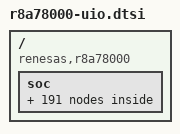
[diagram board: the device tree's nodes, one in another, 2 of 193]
// SPDX-License-Identifier: (GPL-2.0-only OR BSD-2-Clause)
/*
 * Device Tree Source fragment for UIO support on the R-Car X5H (R8A78000) SoC
 *
 * Copyright (C) 2025 Renesas Electronics Corp.
 */

#include <dt-bindings/ipmmu/rcar-ipmmu.h>
#include "r8a78000.dtsi"

/ {
	compatible = "renesas,r8a78000", "renesas,r8a78000-uio";

	soc: soc {
		imrlx7_ims00: ims@c1800000{
			compatible = "generic-uio";
			reg = <0 0xc1800000 0 0x10000>;
			interrupts = <GIC_SPI 606 IRQ_TYPE_LEVEL_HIGH>;
			clocks = <&scmi_clk X5H_CLOCK_ID_IMN_IMS00>;
			power-domains = <&scmi_devpd X5H_POWER_DOMAIN_ID_IM0>;
			linux,uio-name = "ims_00";
		};

		imrlx7_ims01: ims@c1810000{
			compatible = "generic-uio";
			reg = <0 0xc1810000 0 0x10000>;
			interrupts = <GIC_SPI 607 IRQ_TYPE_LEVEL_HIGH>;
			clocks = <&scmi_clk X5H_CLOCK_ID_IMN_IMS01>;
			power-domains = <&scmi_devpd X5H_POWER_DOMAIN_ID_IM0>;
			linux,uio-name = "ims_01";
		};

		imrlx7_ims02: ims@c1820000{
			compatible = "generic-uio";
			reg = <0 0xc1820000 0 0x10000>;
			interrupts = <GIC_SPI 608 IRQ_TYPE_LEVEL_HIGH>;
			clocks = <&scmi_clk X5H_CLOCK_ID_IMN_IMS02>;
			power-domains = <&scmi_devpd X5H_POWER_DOMAIN_ID_IM1>;
			linux,uio-name = "ims_02";
		};

		imrlx7_ims03: ims@c1830000{
			compatible = "generic-uio";
			reg = <0 0xc1830000 0 0x10000>;
			interrupts = <GIC_SPI 609 IRQ_TYPE_LEVEL_HIGH>;
			clocks = <&scmi_clk X5H_CLOCK_ID_IMN_IMS03>;
			power-domains = <&scmi_devpd X5H_POWER_DOMAIN_ID_IM1>;
			linux,uio-name = "ims_03";
		};

		imrlx7_imr00: imr@c1900000 {
			compatible = "generic-uio";
			reg = <0 0xc1900000 0 0x10000>;
			interrupts = <GIC_SPI 614 IRQ_TYPE_LEVEL_HIGH>;
			clocks = <&scmi_clk X5H_CLOCK_ID_IMN_IMR000>;
			power-domains = <&scmi_devpd X5H_POWER_DOMAIN_ID_IM0>;
			linux,uio-name = "imr_00";
		};

		imrlx7_imr01: imr@c1910000 {
			compatible = "generic-uio";
			reg = <0 0xc1910000 0 0x10000>;
			interrupts = <GIC_SPI 615 IRQ_TYPE_LEVEL_HIGH>;
			clocks = <&scmi_clk X5H_CLOCK_ID_IMN_IMR001>;
			power-domains = <&scmi_devpd X5H_POWER_DOMAIN_ID_IM1>;
			linux,uio-name = "imr_01";
		};

		imrlx7_ims10: ims@c1c00000 {
			compatible = "generic-uio";
			reg = <0 0xc1c00000 0 0x10000>;
			interrupts = <GIC_SPI 610 IRQ_TYPE_LEVEL_HIGH>;
			clocks = <&scmi_clk X5H_CLOCK_ID_IMS_IMS00>;
			power-domains = <&scmi_devpd X5H_POWER_DOMAIN_ID_IM1>;
			linux,uio-name = "ims_10";
		};

		imrlx7_ims11: ims@c1c10000 {
			compatible = "generic-uio";
			reg = <0 0xc1c10000 0 0x10000>;
			interrupts = <GIC_SPI 611 IRQ_TYPE_LEVEL_HIGH>;
			clocks = <&scmi_clk X5H_CLOCK_ID_IMS_IMS01>;
			power-domains = <&scmi_devpd X5H_POWER_DOMAIN_ID_IM2>;
			linux,uio-name = "ims_11";
		};

		imrlx7_ims12: ims@c1c20000 {
			compatible = "generic-uio";
			reg = <0 0xc1c20000 0 0x10000>;
			interrupts = <GIC_SPI 612 IRQ_TYPE_LEVEL_HIGH>;
			clocks = <&scmi_clk X5H_CLOCK_ID_IMS_IMS02>;
			power-domains = <&scmi_devpd X5H_POWER_DOMAIN_ID_IM3>;
			linux,uio-name = "ims_12";
		};

		imrlx7_ims13: ims@c1c30000 {
			compatible = "generic-uio";
			reg = <0 0xc1c30000 0 0x10000>;
			interrupts = <GIC_SPI 613 IRQ_TYPE_LEVEL_HIGH>;
			clocks = <&scmi_clk X5H_CLOCK_ID_IMS_IMS03>;
			power-domains = <&scmi_devpd X5H_POWER_DOMAIN_ID_IM3>;
			linux,uio-name = "ims_13";
		};

		imrlx7_imr10: imr@c1d00000 {
			compatible = "generic-uio";
			reg = <0 0xc1d00000 0 0x10000>;
			interrupts = <GIC_SPI 616 IRQ_TYPE_LEVEL_HIGH>;
			clocks = <&scmi_clk X5H_CLOCK_ID_IMS_IMR000>;
			power-domains = <&scmi_devpd X5H_POWER_DOMAIN_ID_IM2>;
			linux,uio-name = "imr_10";
		};

		imrlx7_imr11: imr@c1d10000 {
			compatible = "generic-uio";
			reg = <0 0xc1d10000 0 0x10000>;
			interrupts = <GIC_SPI 617 IRQ_TYPE_LEVEL_HIGH>;
			clocks = <&scmi_clk X5H_CLOCK_ID_IMS_IMR001>;
			power-domains = <&scmi_devpd X5H_POWER_DOMAIN_ID_IM3>;
			linux,uio-name = "imr_11";
		};

		cisp0: cisp@c4000000 {
			compatible = "generic-uio";
			reg = <0 0xc4000000 0 0x100000>;
			interrupts = <GIC_SPI 502 IRQ_TYPE_LEVEL_HIGH>;
			clocks = <&scmi_clk X5H_CLOCK_ID_ISP0>;
			power-domains = <&scmi_devpd X5H_POWER_DOMAIN_ID_VIO0>;
			linux,uio-name = "cisp_00";
		};

		cisp1: cisp@c4100000 {
			compatible = "generic-uio";
			reg = <0 0xc4100000 0 0x100000>;
			interrupts = <GIC_SPI 503 IRQ_TYPE_LEVEL_HIGH>;
			clocks = <&scmi_clk X5H_CLOCK_ID_ISP1>;
			power-domains = <&scmi_devpd X5H_POWER_DOMAIN_ID_VIO1>;
			linux,uio-name = "cisp_01";
		};

		cisp2: cisp@c4200000 {
			compatible = "generic-uio";
			reg = <0 0xc4200000 0 0x100000>;
			interrupts = <GIC_SPI 504 IRQ_TYPE_LEVEL_HIGH>;
			clocks = <&scmi_clk X5H_CLOCK_ID_ISP2>;
			power-domains = <&scmi_devpd X5H_POWER_DOMAIN_ID_VIO2>;
			linux,uio-name = "cisp_02";
		};

		cisp3: cisp@c4300000 {
			compatible = "generic-uio";
			reg = <0 0xc4300000 0 0x100000>;
			interrupts = <GIC_SPI 505 IRQ_TYPE_LEVEL_HIGH>;
			clocks = <&scmi_clk X5H_CLOCK_ID_ISP3>;
			power-domains = <&scmi_devpd X5H_POWER_DOMAIN_ID_VIO3>;
			linux,uio-name = "cisp_03";
		};

		tisp0: tisp@c4700000 {
			compatible = "generic-uio";
			reg = <0 0xc4700000 0 0x20000>;
			interrupts = <GIC_SPI 506 IRQ_TYPE_LEVEL_HIGH>;
			clocks = <&scmi_clk X5H_CLOCK_ID_ISPCS0>;
			power-domains = <&scmi_devpd X5H_POWER_DOMAIN_ID_VIO0>;
			linux,uio-name = "tisp_00";
		};

		tisp1: tisp@c4720000 {
			compatible = "generic-uio";
			reg = <0 0xc4720000 0 0x20000>;
			interrupts = <GIC_SPI 507 IRQ_TYPE_LEVEL_HIGH>;
			clocks = <&scmi_clk X5H_CLOCK_ID_ISPCS1>;
			power-domains = <&scmi_devpd X5H_POWER_DOMAIN_ID_VIO1>;
			linux,uio-name = "tisp_01";
		};

		tisp2: tisp@c4740000 {
			compatible = "generic-uio";
			reg = <0 0xc4740000 0 0x20000>;
			interrupts = <GIC_SPI 508 IRQ_TYPE_LEVEL_HIGH>;
			clocks = <&scmi_clk X5H_CLOCK_ID_ISPCS2>;
			power-domains = <&scmi_devpd X5H_POWER_DOMAIN_ID_VIO2>;
			linux,uio-name = "tisp_02";
		};

		tisp3: tisp@c4760000 {
			compatible = "generic-uio";
			reg = <0 0xc4760000 0 0x20000>;
			interrupts = <GIC_SPI 509 IRQ_TYPE_LEVEL_HIGH>;
			clocks = <&scmi_clk X5H_CLOCK_ID_ISPCS3>;
			power-domains = <&scmi_devpd X5H_POWER_DOMAIN_ID_VIO3>;
			linux,uio-name = "tisp_03";
		};
		vspx0: vspx@c4880000 {
			compatible = "generic-uio";
			reg = <0 0xc4880000 0 0x4000>;
			interrupts = <GIC_SPI 647 IRQ_TYPE_LEVEL_HIGH>;
			clocks = <&scmi_clk X5H_CLOCK_ID_VSPX0>;
			power-domains = <&scmi_devpd X5H_POWER_DOMAIN_ID_VIO0>;
			linux,uio-name = "vspx_00";
		};

		vspx1: vspx@c4884000 {
			compatible = "generic-uio";
			reg = <0 0xc4884000 0 0x4000>;
			interrupts = <GIC_SPI 648 IRQ_TYPE_LEVEL_HIGH>;
			clocks = <&scmi_clk X5H_CLOCK_ID_VSPX1>;
			power-domains = <&scmi_devpd X5H_POWER_DOMAIN_ID_VIO1>;
			linux,uio-name = "vspx_01";
		};

		vspx2: vspx@c4888000 {
			compatible = "generic-uio";
			reg = <0 0xc4888000 0 0x4000>;
			interrupts = <GIC_SPI 649 IRQ_TYPE_LEVEL_HIGH>;
			clocks = <&scmi_clk X5H_CLOCK_ID_VSPX2>;
			power-domains = <&scmi_devpd X5H_POWER_DOMAIN_ID_VIO2>;
			linux,uio-name = "vspx_02";
		};

		vspx3: vspx@c488c000 {
			compatible = "generic-uio";
			reg = <0 0xc488c000 0 0x4000>;
			interrupts = <GIC_SPI 650 IRQ_TYPE_LEVEL_HIGH>;
			clocks = <&scmi_clk X5H_CLOCK_ID_VSPX3>;
			power-domains = <&scmi_devpd X5H_POWER_DOMAIN_ID_VIO3>;
			linux,uio-name = "vspx_03";
		};

		fcpvx0: fcpvx@c48a4000 {
			compatible = "generic-uio";
			reg = <0 0xc48a4000 0 0x1000>;
			clocks = <&scmi_clk X5H_CLOCK_ID_FCPVX0>;
			power-domains = <&scmi_devpd X5H_POWER_DOMAIN_ID_VIO0>;
			linux,uio-name = "fcpvx_00";
		};

		fcpvx1: fcpvx@c48a5000 {
			compatible = "generic-uio";
			reg = <0 0xc48a5000 0 0x1000>;
			clocks = <&scmi_clk X5H_CLOCK_ID_FCPVX1>;
			power-domains = <&scmi_devpd X5H_POWER_DOMAIN_ID_VIO1>;
			linux,uio-name = "fcpvx_01";
		};

		fcpvx2: fcpvx@c48a6000 {
			compatible = "generic-uio";
			reg = <0 0xc48a6000 0 0x1000>;
			clocks = <&scmi_clk X5H_CLOCK_ID_FCPVX2>;
			power-domains = <&scmi_devpd X5H_POWER_DOMAIN_ID_VIO2>;
			linux,uio-name = "fcpvx_02";
		};

		fcpvx3: fcpvx@c48a7000 {
			compatible = "generic-uio";
			reg = <0 0xc48a7000 0 0x1000>;
			clocks = <&scmi_clk X5H_CLOCK_ID_FCPVX3>;
			power-domains = <&scmi_devpd X5H_POWER_DOMAIN_ID_VIO3>;
			linux,uio-name = "fcpvx_03";
		};

		vcp5_0: dspss@c3000000 {
			compatible = "generic-uio";
			reg = <0 0xc3000000 0 0x10000>;
			interrupts = <GIC_SPI 651 IRQ_TYPE_LEVEL_HIGH>;
			clocks = <&scmi_clk X5H_CLOCK_ID_VIPN_VCP5X0>;
			power-domains = <&scmi_devpd X5H_POWER_DOMAIN_ID_VCN>;
			linux,uio-name = "vcp5_00";
		};

		vcp5_00_01 {
			compatible = "generic-uio";
			reg = <0 0xc3000000 0 0x10000>;
			interrupts = <GIC_SPI 655 IRQ_TYPE_LEVEL_HIGH>;
			clocks = <&scmi_clk X5H_CLOCK_ID_VIPN_VCP5X0>;
			power-domains = <&scmi_devpd X5H_POWER_DOMAIN_ID_VCN>;
			linux,uio-name = "irq_vcp5_00_01";
		};

		vcp5_1: dspss@c3002000 {
			compatible = "generic-uio";
			reg = <0 0xc3002000 0 0x10000>;
			interrupts = <GIC_SPI 652 IRQ_TYPE_LEVEL_HIGH>;
			clocks = <&scmi_clk X5H_CLOCK_ID_VIPN_VCP5X0>;
			power-domains = <&scmi_devpd X5H_POWER_DOMAIN_ID_VCN>;
			linux,uio-name = "vcp5_01";
		};

		vcp5_01_01 {
			compatible = "generic-uio";
			reg = <0 0xc3002000 0 0x10000>;
			interrupts = <GIC_SPI 656 IRQ_TYPE_LEVEL_HIGH>;
			clocks = <&scmi_clk X5H_CLOCK_ID_VIPN_VCP5X0>;
			power-domains = <&scmi_devpd X5H_POWER_DOMAIN_ID_VCN>;
			linux,uio-name = "irq_vcp5_01_01";
		};

		vcp5_2: dspss@c3400000 {
			compatible = "generic-uio";
			reg = <0 0xc3400000 0 0x10000>;
			interrupts = <GIC_SPI 653 IRQ_TYPE_LEVEL_HIGH>;
			clocks = <&scmi_clk X5H_CLOCK_ID_VIPN_VCP5X1>;
			power-domains = <&scmi_devpd X5H_POWER_DOMAIN_ID_VCS>;
			linux,uio-name = "vcp5_02";
		};

		vcp5_02_01 {
			compatible = "generic-uio";
			reg = <0 0xc3400000 0 0x10000>;
			interrupts = <GIC_SPI 657 IRQ_TYPE_LEVEL_HIGH>;
			clocks = <&scmi_clk X5H_CLOCK_ID_VIPN_VCP5X1>;
			power-domains = <&scmi_devpd X5H_POWER_DOMAIN_ID_VCS>;
			linux,uio-name = "irq_vcp5_02_01";
		};

		vcp5_3: dspss@c3402000 {
			compatible = "generic-uio";
			reg = <0 0xc3402000 0 0x10000>;
			interrupts = <GIC_SPI 654 IRQ_TYPE_LEVEL_HIGH>;
			clocks = <&scmi_clk X5H_CLOCK_ID_VIPN_VCP5X1>;
			power-domains = <&scmi_devpd X5H_POWER_DOMAIN_ID_VCS>;
			linux,uio-name = "vcp5_03";
		};

		vcp5_03_01 {
			compatible = "generic-uio";
			reg = <0 0xc3402000 0 0x10000>;
			interrupts = <GIC_SPI 658 IRQ_TYPE_LEVEL_HIGH>;
			clocks = <&scmi_clk X5H_CLOCK_ID_VIPN_VCP5X1>;
			power-domains = <&scmi_devpd X5H_POWER_DOMAIN_ID_VCS>;
			linux,uio-name = "irq_vcp5_03_01";
		};

		fcpc0: fcpc@c3008000 {
			compatible = "generic-uio";
			reg = <0 0xc3008000 0 0x1000>;
			clocks = <&scmi_clk X5H_CLOCK_ID_VIPN_FCPCS0>;
			power-domains = <&scmi_devpd X5H_POWER_DOMAIN_ID_VCN>;
			linux,uio-name = "fcpc_00";
		};

		fcpc1: fcpc@c3009000 {
			compatible = "generic-uio";
			reg = <0 0xc3009000 0 0x1000>;
			clocks = <&scmi_clk X5H_CLOCK_ID_VIPN_FCPCS0>;
			power-domains = <&scmi_devpd X5H_POWER_DOMAIN_ID_VCN>;
			linux,uio-name = "fcpc_01";
		};

		fcpc2: fcpc@c3408000 {
			compatible = "generic-uio";
			reg = <0 0xc3408000 0 0x1000>;
			clocks = <&scmi_clk X5H_CLOCK_ID_VIPN_FCPCS1>;
			power-domains = <&scmi_devpd X5H_POWER_DOMAIN_ID_VCS>;
			linux,uio-name = "fcpc_02";
		};

		fcpc3: fcpc@c3409000 {
			compatible = "generic-uio";
			reg = <0 0xc3409000 0 0x1000>;
			clocks = <&scmi_clk X5H_CLOCK_ID_VIPN_FCPCS1>;
			power-domains = <&scmi_devpd X5H_POWER_DOMAIN_ID_VCS>;
			linux,uio-name = "fcpc_03";
		};

		rsipe0: rsipe@19300000 {
			compatible = "generic-uio";
			reg = <0 0x19300000 0 0x8000>;
			interrupts = <GIC_SPI 4187 IRQ_TYPE_LEVEL_HIGH>;
			clocks = <&scmi_clk X5H_CLOCK_ID_CRAC0>;
			//power-domains = <&scmi_devpd X5H_POWER_DOMAIN_ID_PD_APL>;
			resets = <&scmi_reset X5H_RESET_DOMAIN_ID_CRAC0>;
			linux,uio-name = "rsip_e_00";
		};

		rsipe1: rsipe@19308000 {
			compatible = "generic-uio";
			reg = <0 0x19308000 0 0x8000>;
			interrupts = <GIC_SPI 4188 IRQ_TYPE_LEVEL_HIGH>;
			clocks = <&scmi_clk X5H_CLOCK_ID_CRAC1>;
			//power-domains = <&scmi_devpd X5H_POWER_DOMAIN_ID_PD_APL>;
			resets = <&scmi_reset X5H_RESET_DOMAIN_ID_CRAC1>;
			linux,uio-name = "rsip_e_01";
		};

		rsipe2: rsipe@19310000 {
			compatible = "generic-uio";
			reg = <0 0x19310000 0 0x8000>;
			interrupts = <GIC_SPI 4189 IRQ_TYPE_LEVEL_HIGH>;
			clocks = <&scmi_clk X5H_CLOCK_ID_CRAC2>;
			//power-domains = <&scmi_devpd X5H_POWER_DOMAIN_ID_PD_APL>;
			resets = <&scmi_reset X5H_RESET_DOMAIN_ID_CRAC2>;
			linux,uio-name = "rsip_e_02";
		};

		rsipe3: rsipe@19318000 {
			compatible = "generic-uio";
			reg = <0 0x19318000 0 0x8000>;
			interrupts = <GIC_SPI 4190 IRQ_TYPE_LEVEL_HIGH>;
			clocks = <&scmi_clk X5H_CLOCK_ID_CRAC3>;
			//power-domains = <&scmi_devpd X5H_POWER_DOMAIN_ID_PD_APL>;
			resets = <&scmi_reset X5H_RESET_DOMAIN_ID_CRAC3>;
			linux,uio-name = "rsip_e_03";
		};

		rsipe4: rsipe@19320000 {
			compatible = "generic-uio";
			reg = <0 0x19320000 0 0x8000>;
			interrupts = <GIC_SPI 4191 IRQ_TYPE_LEVEL_HIGH>;
			clocks = <&scmi_clk X5H_CLOCK_ID_CRAC4>;
			//power-domains = <&scmi_devpd X5H_POWER_DOMAIN_ID_PD_APL>;
			resets = <&scmi_reset X5H_RESET_DOMAIN_ID_CRAC4>;
			linux,uio-name = "rsip_e_04";
		};

		rsipe5: rsipe@19328000 {
			compatible = "generic-uio";
			reg = <0 0x19328000 0 0x8000>;
			interrupts = <GIC_SPI 4192 IRQ_TYPE_LEVEL_HIGH>;
			clocks = <&scmi_clk X5H_CLOCK_ID_CRAC5>;
			//power-domains = <&scmi_devpd X5H_POWER_DOMAIN_ID_PD_APL>;
			resets = <&scmi_reset X5H_RESET_DOMAIN_ID_CRAC5>;
			linux,uio-name = "rsip_e_05";
		};

		rsipe6: rsipe@19330000 {
			compatible = "generic-uio";
			reg = <0 0x19330000 0 0x8000>;
			interrupts = <GIC_SPI 4193 IRQ_TYPE_LEVEL_HIGH>;
			clocks = <&scmi_clk X5H_CLOCK_ID_CRAC6>;
			//power-domains = <&scmi_devpd X5H_POWER_DOMAIN_ID_PD_APL>;
			resets = <&scmi_reset X5H_RESET_DOMAIN_ID_CRAC6>;
			linux,uio-name = "rsip_e_06";
		};

		rsipe7: rsipe@19338000 {
			compatible = "generic-uio";
			reg = <0 0x19338000 0 0x8000>;
			interrupts = <GIC_SPI 4194 IRQ_TYPE_LEVEL_HIGH>;
			clocks = <&scmi_clk X5H_CLOCK_ID_CRAC7>;
			//power-domains = <&scmi_devpd X5H_POWER_DOMAIN_ID_PD_APL>;
			resets = <&scmi_reset X5H_RESET_DOMAIN_ID_CRAC7>;
			linux,uio-name = "rsip_e_07";
		};

		rsipe8: rsipe@19340000 {
			compatible = "generic-uio";
			reg = <0 0x19340000 0 0x8000>;
			interrupts = <GIC_SPI 4195 IRQ_TYPE_LEVEL_HIGH>;
			clocks = <&scmi_clk X5H_CLOCK_ID_CRAC8>;
			//power-domains = <&scmi_devpd X5H_POWER_DOMAIN_ID_PD_APL>;
			resets = <&scmi_reset X5H_RESET_DOMAIN_ID_CRAC8>;
			linux,uio-name = "rsip_e_08";
		};

		rsipe9: rsipe@19348000 {
			compatible = "generic-uio";
			reg = <0 0x19348000 0 0x8000>;
			interrupts = <GIC_SPI 4196 IRQ_TYPE_LEVEL_HIGH>;
			clocks = <&scmi_clk X5H_CLOCK_ID_CRAC9>;
			//power-domains = <&scmi_devpd X5H_POWER_DOMAIN_ID_PD_APL>;
			resets = <&scmi_reset X5H_RESET_DOMAIN_ID_CRAC9>;
			linux,uio-name = "rsip_e_09";
		};

		rsipe10: rsipe@19350000 {
			compatible = "generic-uio";
			reg = <0 0x19350000 0 0x8000>;
			interrupts = <GIC_SPI 4197 IRQ_TYPE_LEVEL_HIGH>;
			clocks = <&scmi_clk X5H_CLOCK_ID_CRAC10>;
			//power-domains = <&scmi_devpd X5H_POWER_DOMAIN_ID_PD_APL>;
			resets = <&scmi_reset X5H_RESET_DOMAIN_ID_CRAC10>;
			linux,uio-name = "rsip_e_10";
		};

		rsipe11: rsipe@19358000 {
			compatible = "generic-uio";
			reg = <0 0x19358000 0 0x8000>;
			interrupts = <GIC_SPI 4198 IRQ_TYPE_LEVEL_HIGH>;
			clocks = <&scmi_clk X5H_CLOCK_ID_CRAC11>;
			//power-domains = <&scmi_devpd X5H_POWER_DOMAIN_ID_PD_APL>;
			resets = <&scmi_reset X5H_RESET_DOMAIN_ID_CRAC11>;
			linux,uio-name = "rsip_e_11";
		};

		rsipe12: rsipe@19360000 {
			compatible = "generic-uio";
			reg = <0 0x19360000 0 0x8000>;
			interrupts = <GIC_SPI 4199 IRQ_TYPE_LEVEL_HIGH>;
			clocks = <&scmi_clk X5H_CLOCK_ID_CRAC12>;
			//power-domains = <&scmi_devpd X5H_POWER_DOMAIN_ID_PD_APL>;
			resets = <&scmi_reset X5H_RESET_DOMAIN_ID_CRAC12>;
			linux,uio-name = "rsip_e_12";
		};

		rsipe13: rsipe@19368000 {
			compatible = "generic-uio";
			reg = <0 0x19368000 0 0x8000>;
			interrupts = <GIC_SPI 4200 IRQ_TYPE_LEVEL_HIGH>;
			clocks = <&scmi_clk X5H_CLOCK_ID_CRAC13>;
			//power-domains = <&scmi_devpd X5H_POWER_DOMAIN_ID_PD_APL>;
			resets = <&scmi_reset X5H_RESET_DOMAIN_ID_CRAC13>;
			linux,uio-name = "rsip_e_13";
		};

		rsipe14: rsipe@19370000 {
			compatible = "generic-uio";
			reg = <0 0x19370000 0 0x8000>;
			interrupts = <GIC_SPI 4201 IRQ_TYPE_LEVEL_HIGH>;
			clocks = <&scmi_clk X5H_CLOCK_ID_CRAC14>;
			//power-domains = <&scmi_devpd X5H_POWER_DOMAIN_ID_PD_APL>;
			resets = <&scmi_reset X5H_RESET_DOMAIN_ID_CRAC14>;
			linux,uio-name = "rsip_e_14";
		};

		rsipe15: rsipe@19378000 {
			compatible = "generic-uio";
			reg = <0 0x19378000 0 0x8000>;
			interrupts = <GIC_SPI 4202 IRQ_TYPE_LEVEL_HIGH>;
			clocks = <&scmi_clk X5H_CLOCK_ID_CRAC15>;
			//power-domains = <&scmi_devpd X5H_POWER_DOMAIN_ID_PD_APL>;
			resets = <&scmi_reset X5H_RESET_DOMAIN_ID_CRAC15>;
			linux,uio-name = "rsip_e_15";
		};

		rsipe16: rsipe@19380000 {
			compatible = "generic-uio";
			reg = <0 0x19380000 0 0x8000>;
			interrupts = <GIC_SPI 4203 IRQ_TYPE_LEVEL_HIGH>;
			clocks = <&scmi_clk X5H_CLOCK_ID_CRAC16>;
			//power-domains = <&scmi_devpd X5H_POWER_DOMAIN_ID_PD_APL>;
			resets = <&scmi_reset X5H_RESET_DOMAIN_ID_CRAC16>;
			linux,uio-name = "rsip_e_16";
		};

		rsipe17: rsipe@19388000 {
			compatible = "generic-uio";
			reg = <0 0x19388000 0 0x8000>;
			interrupts = <GIC_SPI 4204 IRQ_TYPE_LEVEL_HIGH>;
			clocks = <&scmi_clk X5H_CLOCK_ID_CRAC17>;
			//power-domains = <&scmi_devpd X5H_POWER_DOMAIN_ID_PD_APL>;
			resets = <&scmi_reset X5H_RESET_DOMAIN_ID_CRAC17>;
			linux,uio-name = "rsip_e_17";
		};

		rsipe18: rsipe@19390000 {
			compatible = "generic-uio";
			reg = <0 0x19390000 0 0x8000>;
			interrupts = <GIC_SPI 4205 IRQ_TYPE_LEVEL_HIGH>;
			clocks = <&scmi_clk X5H_CLOCK_ID_CRAC18>;
			//power-domains = <&scmi_devpd X5H_POWER_DOMAIN_ID_PD_APL>;
			resets = <&scmi_reset X5H_RESET_DOMAIN_ID_CRAC18>;
			linux,uio-name = "rsip_e_18";
		};

		rsipe19: rsipe@19398000 {
			compatible = "generic-uio";
			reg = <0 0x19398000 0 0x8000>;
			interrupts = <GIC_SPI 4206 IRQ_TYPE_LEVEL_HIGH>;
			clocks = <&scmi_clk X5H_CLOCK_ID_CRAC19>;
			//power-domains = <&scmi_devpd X5H_POWER_DOMAIN_ID_PD_APL>;
			resets = <&scmi_reset X5H_RESET_DOMAIN_ID_CRAC19>;
			linux,uio-name = "rsip_e_19";
		};

		rsipm: rsipm@18980000 {
			compatible = "generic-uio";
			reg = <0 0x18980000 0 0x10000>;
			linux,uio-name = "rsip_m_ts_cmd_00";
		};

		rsipm_reserved_mem1: rsipm@10100000 {
			compatible = "generic-uio";
			reg = <0 0x10100000 0 0x100000>;
			linux,uio-name = "rsip_m_shared_01";
		};

		rsipm_reserved_mem2: rsipm@4d000000 {
			compatible = "generic-uio";
			reg = <0 0x4d000000 0 0x600000>;
			linux,uio-name = "rsip_m_shared_02";
		};

		rsipe00: rsipe@19440000 {
			compatible = "generic-uio";
			reg = <0 0x19440000 0 0x1000>;
			linux,uio-name = "rsip_e_stb_00";
		};

		ostm0: ostm@1c060000 {
			compatible = "generic-uio";
			reg = <0 0x1c060000 0 0x1000>;
			interrupts = <GIC_SPI 4135 IRQ_TYPE_LEVEL_HIGH>;
			clocks = <&scmi_clk X5H_CLOCK_ID_OSTM0>;
			//power-domains = <&scmi_devpd X5H_POWER_DOMAIN_ID_PD_APL>;
			resets = <&scmi_reset X5H_RESET_DOMAIN_ID_OSTM0>;
			linux,uio-name = "ostm_00";
		};

		ostm1: ostm@1c061000 {
			compatible = "generic-uio";
			reg = <0 0x1c061000 0 0x1000>;
			interrupts = <GIC_SPI 4136 IRQ_TYPE_LEVEL_HIGH>;
			clocks = <&scmi_clk X5H_CLOCK_ID_OSTM1>;
			//power-domains = <&scmi_devpd X5H_POWER_DOMAIN_ID_PD_APL>;
			resets = <&scmi_reset X5H_RESET_DOMAIN_ID_OSTM1>;
			linux,uio-name = "ostm_01";
		};

		ostm2: ostm@1c062000 {
			compatible = "generic-uio";
			reg = <0 0x1c062000 0 0x1000>;
			interrupts = <GIC_SPI 4137 IRQ_TYPE_LEVEL_HIGH>;
			clocks = <&scmi_clk X5H_CLOCK_ID_OSTM2>;
			//power-domains = <&scmi_devpd X5H_POWER_DOMAIN_ID_PD_APL>;
			resets = <&scmi_reset X5H_RESET_DOMAIN_ID_OSTM2>;
			linux,uio-name = "ostm_02";
		};

		ostm3: ostm@1c063000 {
			compatible = "generic-uio";
			reg = <0 0x1c063000 0 0x1000>;
			interrupts = <GIC_SPI 4138 IRQ_TYPE_LEVEL_HIGH>;
			clocks = <&scmi_clk X5H_CLOCK_ID_OSTM3>;
			//power-domains = <&scmi_devpd X5H_POWER_DOMAIN_ID_PD_APL>;
			resets = <&scmi_reset X5H_RESET_DOMAIN_ID_OSTM3>;
			linux,uio-name = "ostm_03";
		};

		ostm4: ostm@1c064000 {
			compatible = "generic-uio";
			reg = <0 0x1c064000 0 0x1000>;
			interrupts = <GIC_SPI 4139 IRQ_TYPE_LEVEL_HIGH>;
			clocks = <&scmi_clk X5H_CLOCK_ID_OSTM4>;
			//power-domains = <&scmi_devpd X5H_POWER_DOMAIN_ID_PD_APL>;
			resets = <&scmi_reset X5H_RESET_DOMAIN_ID_OSTM4>;
			linux,uio-name = "ostm_04";
		};

		ostm5: ostm@1c065000 {
			compatible = "generic-uio";
			reg = <0 0x1c065000 0 0x1000>;
			interrupts = <GIC_SPI 4140 IRQ_TYPE_LEVEL_HIGH>;
			clocks = <&scmi_clk X5H_CLOCK_ID_OSTM5>;
			//power-domains = <&scmi_devpd X5H_POWER_DOMAIN_ID_PD_APL>;
			resets = <&scmi_reset X5H_RESET_DOMAIN_ID_OSTM5>;
			linux,uio-name = "ostm_05";
		};

		vin_00: video@c4900000 {
			compatible = "generic-uio";
			reg = <0 0xc4900000 0 0x1000>;
			interrupts = <GIC_SPI 510 IRQ_TYPE_LEVEL_HIGH>;
			power-domains = <&scmi_devpd X5H_POWER_DOMAIN_ID_VIO0>;
			clocks = <&scmi_clk X5H_CLOCK_ID_VIN000>;
			resets = <&scmi_reset X5H_RESET_DOMAIN_ID_VIN000>;
			linux,uio-name = "vin_00";
		};

		vin_01: video@c4901000 {
			compatible = "generic-uio";
			reg = <0 0xc4901000 0 0x1000>;
			interrupts = <GIC_SPI 511 IRQ_TYPE_LEVEL_HIGH>;
			power-domains = <&scmi_devpd X5H_POWER_DOMAIN_ID_VIO0>;
			clocks = <&scmi_clk X5H_CLOCK_ID_VIN001>;
			resets = <&scmi_reset X5H_RESET_DOMAIN_ID_VIN001>;
			linux,uio-name = "vin_01";
		};

		vin_02: video@c4902000 {
			compatible = "generic-uio";
			reg = <0 0xc4902000 0 0x1000>;
			interrupts = <GIC_SPI 512 IRQ_TYPE_LEVEL_HIGH>;
			power-domains = <&scmi_devpd X5H_POWER_DOMAIN_ID_VIO0>;
			clocks = <&scmi_clk X5H_CLOCK_ID_VIN002>;
			resets = <&scmi_reset X5H_RESET_DOMAIN_ID_VIN002>;
			linux,uio-name = "vin_02";
		};

		vin_03: video@c4903000 {
			compatible = "generic-uio";
			reg = <0 0xc4903000 0 0x1000>;
			interrupts = <GIC_SPI 513 IRQ_TYPE_LEVEL_HIGH>;
			power-domains = <&scmi_devpd X5H_POWER_DOMAIN_ID_VIO0>;
			clocks = <&scmi_clk X5H_CLOCK_ID_VIN003>;
			resets = <&scmi_reset X5H_RESET_DOMAIN_ID_VIN003>;
			linux,uio-name = "vin_03";
		};

		vin_04: video@c4904000 {
			compatible = "generic-uio";
			reg = <0 0xc4904000 0 0x1000>;
			interrupts = <GIC_SPI 514 IRQ_TYPE_LEVEL_HIGH>;
			power-domains = <&scmi_devpd X5H_POWER_DOMAIN_ID_VIO0>;
			clocks = <&scmi_clk X5H_CLOCK_ID_VIN004>;
			resets = <&scmi_reset X5H_RESET_DOMAIN_ID_VIN004>;
			linux,uio-name = "vin_04";
		};

		vin_05: video@c4905000 {
			compatible = "generic-uio";
			reg = <0 0xc4905000 0 0x1000>;
			interrupts = <GIC_SPI 515 IRQ_TYPE_LEVEL_HIGH>;
			power-domains = <&scmi_devpd X5H_POWER_DOMAIN_ID_VIO0>;
			clocks = <&scmi_clk X5H_CLOCK_ID_VIN005>;
			resets = <&scmi_reset X5H_RESET_DOMAIN_ID_VIN005>;
			linux,uio-name = "vin_05";
		};

		vin_06: video@c4906000 {
			compatible = "generic-uio";
			reg = <0 0xc4906000 0 0x1000>;
			interrupts = <GIC_SPI 516 IRQ_TYPE_LEVEL_HIGH>;
			power-domains = <&scmi_devpd X5H_POWER_DOMAIN_ID_VIO0>;
			clocks = <&scmi_clk X5H_CLOCK_ID_VIN006>;
			resets = <&scmi_reset X5H_RESET_DOMAIN_ID_VIN006>;
			linux,uio-name = "vin_06";
		};

		vin_07: video@c4907000 {
			compatible = "generic-uio";
			reg = <0 0xc4907000 0 0x1000>;
			interrupts = <GIC_SPI 517 IRQ_TYPE_LEVEL_HIGH>;
			power-domains = <&scmi_devpd X5H_POWER_DOMAIN_ID_VIO0>;
			clocks = <&scmi_clk X5H_CLOCK_ID_VIN007>;
			resets = <&scmi_reset X5H_RESET_DOMAIN_ID_VIN007>;
			linux,uio-name = "vin_07";
		};

		vin_10: video@c4908000 {
			compatible = "generic-uio";
			reg = <0 0xc4908000 0 0x1000>;
			interrupts = <GIC_SPI 518 IRQ_TYPE_LEVEL_HIGH>;
			power-domains = <&scmi_devpd X5H_POWER_DOMAIN_ID_VIO0>;
			clocks = <&scmi_clk X5H_CLOCK_ID_VIN010>;
			resets = <&scmi_reset X5H_RESET_DOMAIN_ID_VIN010>;
			linux,uio-name = "vin_10";
		};

		vin_11: video@c4909000 {
			compatible = "generic-uio";
			reg = <0 0xc4909000 0 0x1000>;
			interrupts = <GIC_SPI 519 IRQ_TYPE_LEVEL_HIGH>;
			power-domains = <&scmi_devpd X5H_POWER_DOMAIN_ID_VIO0>;
			clocks = <&scmi_clk X5H_CLOCK_ID_VIN011>;
			resets = <&scmi_reset X5H_RESET_DOMAIN_ID_VIN011>;
			linux,uio-name = "vin_11";
		};

		vin_12: video@c490a000 {
			compatible = "generic-uio";
			reg = <0 0xc490a000 0 0x1000>;
			interrupts = <GIC_SPI 520 IRQ_TYPE_LEVEL_HIGH>;
			power-domains = <&scmi_devpd X5H_POWER_DOMAIN_ID_VIO0>;
			clocks = <&scmi_clk X5H_CLOCK_ID_VIN012>;
			resets = <&scmi_reset X5H_RESET_DOMAIN_ID_VIN012>;
			linux,uio-name = "vin_12";
		};

		vin_13: video@c490b000 {
			compatible = "generic-uio";
			reg = <0 0xc490b000 0 0x1000>;
			interrupts = <GIC_SPI 521 IRQ_TYPE_LEVEL_HIGH>;
			power-domains = <&scmi_devpd X5H_POWER_DOMAIN_ID_VIO0>;
			clocks = <&scmi_clk X5H_CLOCK_ID_VIN013>;
			resets = <&scmi_reset X5H_RESET_DOMAIN_ID_VIN013>;
			linux,uio-name = "vin_13";
		};

		vin_14: video@c490c000 {
			compatible = "generic-uio";
			reg = <0 0xc490c000 0 0x1000>;
			interrupts = <GIC_SPI 522 IRQ_TYPE_LEVEL_HIGH>;
			power-domains = <&scmi_devpd X5H_POWER_DOMAIN_ID_VIO0>;
			clocks = <&scmi_clk X5H_CLOCK_ID_VIN014>;
			resets = <&scmi_reset X5H_RESET_DOMAIN_ID_VIN014>;
			linux,uio-name = "vin_14";
		};

		vin_15: video@c490d000 {
			compatible = "generic-uio";
			reg = <0 0xc490d000 0 0x1000>;
			interrupts = <GIC_SPI 523 IRQ_TYPE_LEVEL_HIGH>;
			power-domains = <&scmi_devpd X5H_POWER_DOMAIN_ID_VIO0>;
			clocks = <&scmi_clk X5H_CLOCK_ID_VIN015>;
			resets = <&scmi_reset X5H_RESET_DOMAIN_ID_VIN015>;
			linux,uio-name = "vin_15";
		};

		vin_16: video@c490e000 {
			compatible = "generic-uio";
			reg = <0 0xc490e000 0 0x1000>;
			interrupts = <GIC_SPI 524 IRQ_TYPE_LEVEL_HIGH>;
			power-domains = <&scmi_devpd X5H_POWER_DOMAIN_ID_VIO0>;
			clocks = <&scmi_clk X5H_CLOCK_ID_VIN016>;
			resets = <&scmi_reset X5H_RESET_DOMAIN_ID_VIN016>;
			linux,uio-name = "vin_16";
		};

		vin_17: video@c490f000 {
			compatible = "generic-uio";
			reg = <0 0xc490f000 0 0x1000>;
			interrupts = <GIC_SPI 525 IRQ_TYPE_LEVEL_HIGH>;
			power-domains = <&scmi_devpd X5H_POWER_DOMAIN_ID_VIO0>;
			clocks = <&scmi_clk X5H_CLOCK_ID_VIN017>;
			resets = <&scmi_reset X5H_RESET_DOMAIN_ID_VIN017>;
			linux,uio-name = "vin_17";
		};

		vin_20: video@c4910000 {
			compatible = "generic-uio";
			reg = <0 0xc4910000 0 0x1000>;
			interrupts = <GIC_SPI 526 IRQ_TYPE_LEVEL_HIGH>;
			power-domains = <&scmi_devpd X5H_POWER_DOMAIN_ID_VIO0>;
			clocks = <&scmi_clk X5H_CLOCK_ID_VIN020>;
			resets = <&scmi_reset X5H_RESET_DOMAIN_ID_VIN020>;
			linux,uio-name = "vin_20";
		};

		vin_21: video@c4911000 {
			compatible = "generic-uio";
			reg = <0 0xc4911000 0 0x1000>;
			interrupts = <GIC_SPI 527 IRQ_TYPE_LEVEL_HIGH>;
			power-domains = <&scmi_devpd X5H_POWER_DOMAIN_ID_VIO0>;
			clocks = <&scmi_clk X5H_CLOCK_ID_VIN021>;
			resets = <&scmi_reset X5H_RESET_DOMAIN_ID_VIN021>;
			linux,uio-name = "vin_21";
		};

		vin_22: video@c4912000 {
			compatible = "generic-uio";
			reg = <0 0xc4912000 0 0x1000>;
			interrupts = <GIC_SPI 528 IRQ_TYPE_LEVEL_HIGH>;
			power-domains = <&scmi_devpd X5H_POWER_DOMAIN_ID_VIO0>;
			clocks = <&scmi_clk X5H_CLOCK_ID_VIN022>;
			resets = <&scmi_reset X5H_RESET_DOMAIN_ID_VIN022>;
			linux,uio-name = "vin_22";
		};

		vin_23: video@c4913000 {
			compatible = "generic-uio";
			reg = <0 0xc4913000 0 0x1000>;
			interrupts = <GIC_SPI 529 IRQ_TYPE_LEVEL_HIGH>;
			power-domains = <&scmi_devpd X5H_POWER_DOMAIN_ID_VIO0>;
			clocks = <&scmi_clk X5H_CLOCK_ID_VIN023>;
			resets = <&scmi_reset X5H_RESET_DOMAIN_ID_VIN023>;
			linux,uio-name = "vin_23";
		};

		vin_24: video@c4914000 {
			compatible = "generic-uio";
			reg = <0 0xc4914000 0 0x1000>;
			interrupts = <GIC_SPI 530 IRQ_TYPE_LEVEL_HIGH>;
			power-domains = <&scmi_devpd X5H_POWER_DOMAIN_ID_VIO0>;
			clocks = <&scmi_clk X5H_CLOCK_ID_VIN024>;
			resets = <&scmi_reset X5H_RESET_DOMAIN_ID_VIN024>;
			linux,uio-name = "vin_24";
		};

		vin_25: video@c4915000 {
			compatible = "generic-uio";
			reg = <0 0xc4915000 0 0x1000>;
			interrupts = <GIC_SPI 531 IRQ_TYPE_LEVEL_HIGH>;
			power-domains = <&scmi_devpd X5H_POWER_DOMAIN_ID_VIO0>;
			clocks = <&scmi_clk X5H_CLOCK_ID_VIN025>;
			resets = <&scmi_reset X5H_RESET_DOMAIN_ID_VIN025>;
			linux,uio-name = "vin_25";
		};

		vin_26: video@c4916000 {
			compatible = "generic-uio";
			reg = <0 0xc4916000 0 0x1000>;
			interrupts = <GIC_SPI 532 IRQ_TYPE_LEVEL_HIGH>;
			power-domains = <&scmi_devpd X5H_POWER_DOMAIN_ID_VIO0>;
			clocks = <&scmi_clk X5H_CLOCK_ID_VIN026>;
			resets = <&scmi_reset X5H_RESET_DOMAIN_ID_VIN026>;
			linux,uio-name = "vin_26";
		};

		vin_27: video@c4917000 {
			compatible = "generic-uio";
			reg = <0 0xc4917000 0 0x1000>;
			interrupts = <GIC_SPI 533 IRQ_TYPE_LEVEL_HIGH>;
			power-domains = <&scmi_devpd X5H_POWER_DOMAIN_ID_VIO0>;
			clocks = <&scmi_clk X5H_CLOCK_ID_VIN027>;
			resets = <&scmi_reset X5H_RESET_DOMAIN_ID_VIN027>;
			linux,uio-name = "vin_27";
		};

		vin_30: video@c4918000 {
			compatible = "generic-uio";
			reg = <0 0xc4918000 0 0x1000>;
			interrupts = <GIC_SPI 534 IRQ_TYPE_LEVEL_HIGH>;
			power-domains = <&scmi_devpd X5H_POWER_DOMAIN_ID_VIO1>;
			clocks = <&scmi_clk X5H_CLOCK_ID_VIN030>;
			resets = <&scmi_reset X5H_RESET_DOMAIN_ID_VIN030>;
			linux,uio-name = "vin_30";
		};

		vin_31: video@c4919000 {
			compatible = "generic-uio";
			reg = <0 0xc4919000 0 0x1000>;
			interrupts = <GIC_SPI 535 IRQ_TYPE_LEVEL_HIGH>;
			power-domains = <&scmi_devpd X5H_POWER_DOMAIN_ID_VIO1>;
			clocks = <&scmi_clk X5H_CLOCK_ID_VIN031>;
			resets = <&scmi_reset X5H_RESET_DOMAIN_ID_VIN031>;
			linux,uio-name = "vin_31";
		};

		vin_32: video@c491a000 {
			compatible = "generic-uio";
			reg = <0 0xc491a000 0 0x1000>;
			interrupts = <GIC_SPI 536 IRQ_TYPE_LEVEL_HIGH>;
			power-domains = <&scmi_devpd X5H_POWER_DOMAIN_ID_VIO1>;
			clocks = <&scmi_clk X5H_CLOCK_ID_VIN032>;
			resets = <&scmi_reset X5H_RESET_DOMAIN_ID_VIN032>;
			linux,uio-name = "vin_32";
		};

		vin_33: video@c491b000 {
			compatible = "generic-uio";
			reg = <0 0xc491b000 0 0x1000>;
			interrupts = <GIC_SPI 537 IRQ_TYPE_LEVEL_HIGH>;
			power-domains = <&scmi_devpd X5H_POWER_DOMAIN_ID_VIO1>;
			clocks = <&scmi_clk X5H_CLOCK_ID_VIN033>;
			resets = <&scmi_reset X5H_RESET_DOMAIN_ID_VIN033>;
			linux,uio-name = "vin_33";
		};

		vin_34: video@c491c000 {
			compatible = "generic-uio";
			reg = <0 0xc491c000 0 0x1000>;
			interrupts = <GIC_SPI 538 IRQ_TYPE_LEVEL_HIGH>;
			power-domains = <&scmi_devpd X5H_POWER_DOMAIN_ID_VIO1>;
			clocks = <&scmi_clk X5H_CLOCK_ID_VIN034>;
			resets = <&scmi_reset X5H_RESET_DOMAIN_ID_VIN034>;
			linux,uio-name = "vin_34";
		};

		vin_35: video@c491d000 {
			compatible = "generic-uio";
			reg = <0 0xc491d000 0 0x1000>;
			interrupts = <GIC_SPI 539 IRQ_TYPE_LEVEL_HIGH>;
			power-domains = <&scmi_devpd X5H_POWER_DOMAIN_ID_VIO1>;
			clocks = <&scmi_clk X5H_CLOCK_ID_VIN035>;
			resets = <&scmi_reset X5H_RESET_DOMAIN_ID_VIN035>;
			linux,uio-name = "vin_35";
		};

		vin_36: video@c491e000 {
			compatible = "generic-uio";
			reg = <0 0xc491e000 0 0x1000>;
			interrupts = <GIC_SPI 540 IRQ_TYPE_LEVEL_HIGH>;
			power-domains = <&scmi_devpd X5H_POWER_DOMAIN_ID_VIO1>;
			clocks = <&scmi_clk X5H_CLOCK_ID_VIN036>;
			resets = <&scmi_reset X5H_RESET_DOMAIN_ID_VIN036>;
			linux,uio-name = "vin_36";
		};

		vin_37: video@c491f000 {
			compatible = "generic-uio";
			reg = <0 0xc491f000 0 0x1000>;
			interrupts = <GIC_SPI 541 IRQ_TYPE_LEVEL_HIGH>;
			power-domains = <&scmi_devpd X5H_POWER_DOMAIN_ID_VIO1>;
			clocks = <&scmi_clk X5H_CLOCK_ID_VIN037>;
			resets = <&scmi_reset X5H_RESET_DOMAIN_ID_VIN037>;
			linux,uio-name = "vin_37";
		};

		vin_40: video@c4920000 {
			compatible = "generic-uio";
			reg = <0 0xc4920000 0 0x1000>;
			interrupts = <GIC_SPI 542 IRQ_TYPE_LEVEL_HIGH>;
			power-domains = <&scmi_devpd X5H_POWER_DOMAIN_ID_VIO1>;
			clocks = <&scmi_clk X5H_CLOCK_ID_VIN040>;
			resets = <&scmi_reset X5H_RESET_DOMAIN_ID_VIN040>;
			linux,uio-name = "vin_40";
		};

		vin_41: video@c4921000 {
			compatible = "generic-uio";
			reg = <0 0xc4921000 0 0x1000>;
			interrupts = <GIC_SPI 543 IRQ_TYPE_LEVEL_HIGH>;
			power-domains = <&scmi_devpd X5H_POWER_DOMAIN_ID_VIO1>;
			clocks = <&scmi_clk X5H_CLOCK_ID_VIN041>;
			resets = <&scmi_reset X5H_RESET_DOMAIN_ID_VIN041>;
			linux,uio-name = "vin_41";
		};

		vin_42: video@c4922000 {
			compatible = "generic-uio";
			reg = <0 0xc4922000 0 0x1000>;
			interrupts = <GIC_SPI 544 IRQ_TYPE_LEVEL_HIGH>;
			power-domains = <&scmi_devpd X5H_POWER_DOMAIN_ID_VIO1>;
			clocks = <&scmi_clk X5H_CLOCK_ID_VIN042>;
			resets = <&scmi_reset X5H_RESET_DOMAIN_ID_VIN042>;
			linux,uio-name = "vin_42";
		};

		vin_43: video@c4923000 {
			compatible = "generic-uio";
			reg = <0 0xc4923000 0 0x1000>;
			interrupts = <GIC_SPI 545 IRQ_TYPE_LEVEL_HIGH>;
			power-domains = <&scmi_devpd X5H_POWER_DOMAIN_ID_VIO1>;
			clocks = <&scmi_clk X5H_CLOCK_ID_VIN043>;
			resets = <&scmi_reset X5H_RESET_DOMAIN_ID_VIN043>;
			linux,uio-name = "vin_43";
		};

		vin_44: video@c4924000 {
			compatible = "generic-uio";
			reg = <0 0xc4924000 0 0x1000>;
			interrupts = <GIC_SPI 546 IRQ_TYPE_LEVEL_HIGH>;
			power-domains = <&scmi_devpd X5H_POWER_DOMAIN_ID_VIO1>;
			clocks = <&scmi_clk X5H_CLOCK_ID_VIN044>;
			resets = <&scmi_reset X5H_RESET_DOMAIN_ID_VIN044>;
			linux,uio-name = "vin_44";
		};

		vin_45: video@c4925000 {
			compatible = "generic-uio";
			reg = <0 0xc4925000 0 0x1000>;
			interrupts = <GIC_SPI 547 IRQ_TYPE_LEVEL_HIGH>;
			power-domains = <&scmi_devpd X5H_POWER_DOMAIN_ID_VIO1>;
			clocks = <&scmi_clk X5H_CLOCK_ID_VIN045>;
			resets = <&scmi_reset X5H_RESET_DOMAIN_ID_VIN045>;
			linux,uio-name = "vin_45";
		};

		vin_46: video@c4926000 {
			compatible = "generic-uio";
			reg = <0 0xc4926000 0 0x1000>;
			interrupts = <GIC_SPI 548 IRQ_TYPE_LEVEL_HIGH>;
			power-domains = <&scmi_devpd X5H_POWER_DOMAIN_ID_VIO1>;
			clocks = <&scmi_clk X5H_CLOCK_ID_VIN046>;
			resets = <&scmi_reset X5H_RESET_DOMAIN_ID_VIN046>;
			linux,uio-name = "vin_46";
		};

		vin_47: video@c4927000 {
			compatible = "generic-uio";
			reg = <0 0xc4927000 0 0x1000>;
			interrupts = <GIC_SPI 549 IRQ_TYPE_LEVEL_HIGH>;
			power-domains = <&scmi_devpd X5H_POWER_DOMAIN_ID_VIO1>;
			clocks = <&scmi_clk X5H_CLOCK_ID_VIN047>;
			resets = <&scmi_reset X5H_RESET_DOMAIN_ID_VIN047>;
			linux,uio-name = "vin_47";
		};

		vin_50: video@c4928000 {
			compatible = "generic-uio";
			reg = <0 0xc4928000 0 0x1000>;
			interrupts = <GIC_SPI 550 IRQ_TYPE_LEVEL_HIGH>;
			power-domains = <&scmi_devpd X5H_POWER_DOMAIN_ID_VIO2>;
			clocks = <&scmi_clk X5H_CLOCK_ID_VIN050>;
			resets = <&scmi_reset X5H_RESET_DOMAIN_ID_VIN050>;
			linux,uio-name = "vin_50";
		};

		vin_51: video@c4929000 {
			compatible = "generic-uio";
			reg = <0 0xc4929000 0 0x1000>;
			interrupts = <GIC_SPI 551 IRQ_TYPE_LEVEL_HIGH>;
			power-domains = <&scmi_devpd X5H_POWER_DOMAIN_ID_VIO2>;
			clocks = <&scmi_clk X5H_CLOCK_ID_VIN051>;
			resets = <&scmi_reset X5H_RESET_DOMAIN_ID_VIN051>;
			linux,uio-name = "vin_51";
		};

		vin_52: video@c492a000 {
			compatible = "generic-uio";
			reg = <0 0xc492a000 0 0x1000>;
			interrupts = <GIC_SPI 552 IRQ_TYPE_LEVEL_HIGH>;
			power-domains = <&scmi_devpd X5H_POWER_DOMAIN_ID_VIO2>;
			clocks = <&scmi_clk X5H_CLOCK_ID_VIN052>;
			resets = <&scmi_reset X5H_RESET_DOMAIN_ID_VIN052>;
			linux,uio-name = "vin_52";
		};

		vin_53: video@c492b000 {
			compatible = "generic-uio";
			reg = <0 0xc492b000 0 0x1000>;
			interrupts = <GIC_SPI 553 IRQ_TYPE_LEVEL_HIGH>;
			power-domains = <&scmi_devpd X5H_POWER_DOMAIN_ID_VIO2>;
			clocks = <&scmi_clk X5H_CLOCK_ID_VIN053>;
			resets = <&scmi_reset X5H_RESET_DOMAIN_ID_VIN053>;
			linux,uio-name = "vin_53";
		};

		vin_54: video@c492c000 {
			compatible = "generic-uio";
			reg = <0 0xc492c000 0 0x1000>;
			interrupts = <GIC_SPI 554 IRQ_TYPE_LEVEL_HIGH>;
			power-domains = <&scmi_devpd X5H_POWER_DOMAIN_ID_VIO2>;
			clocks = <&scmi_clk X5H_CLOCK_ID_VIN054>;
			resets = <&scmi_reset X5H_RESET_DOMAIN_ID_VIN054>;
			linux,uio-name = "vin_54";
		};

		vin_55: video@c492d000 {
			compatible = "generic-uio";
			reg = <0 0xc492d000 0 0x1000>;
			interrupts = <GIC_SPI 555 IRQ_TYPE_LEVEL_HIGH>;
			power-domains = <&scmi_devpd X5H_POWER_DOMAIN_ID_VIO2>;
			clocks = <&scmi_clk X5H_CLOCK_ID_VIN055>;
			resets = <&scmi_reset X5H_RESET_DOMAIN_ID_VIN055>;
			linux,uio-name = "vin_55";
		};

		vin_56: video@c492e000 {
			compatible = "generic-uio";
			reg = <0 0xc492e000 0 0x1000>;
			interrupts = <GIC_SPI 556 IRQ_TYPE_LEVEL_HIGH>;
			power-domains = <&scmi_devpd X5H_POWER_DOMAIN_ID_VIO2>;
			clocks = <&scmi_clk X5H_CLOCK_ID_VIN056>;
			resets = <&scmi_reset X5H_RESET_DOMAIN_ID_VIN056>;
			linux,uio-name = "vin_56";
		};

		vin_57: video@c492f000 {
			compatible = "generic-uio";
			reg = <0 0xc492f000 0 0x1000>;
			interrupts = <GIC_SPI 557 IRQ_TYPE_LEVEL_HIGH>;
			power-domains = <&scmi_devpd X5H_POWER_DOMAIN_ID_VIO2>;
			clocks = <&scmi_clk X5H_CLOCK_ID_VIN057>;
			resets = <&scmi_reset X5H_RESET_DOMAIN_ID_VIN057>;
			linux,uio-name = "vin_57";
		};

		vin_60: video@c4930000 {
			compatible = "generic-uio";
			reg = <0 0xc4930000 0 0x1000>;
			interrupts = <GIC_SPI 558 IRQ_TYPE_LEVEL_HIGH>;
			power-domains = <&scmi_devpd X5H_POWER_DOMAIN_ID_VIO2>;
			clocks = <&scmi_clk X5H_CLOCK_ID_VIN060>;
			resets = <&scmi_reset X5H_RESET_DOMAIN_ID_VIN060>;
			linux,uio-name = "vin_60";
		};

		vin_61: video@c4931000 {
			compatible = "generic-uio";
			reg = <0 0xc4931000 0 0x1000>;
			interrupts = <GIC_SPI 559 IRQ_TYPE_LEVEL_HIGH>;
			power-domains = <&scmi_devpd X5H_POWER_DOMAIN_ID_VIO2>;
			clocks = <&scmi_clk X5H_CLOCK_ID_VIN061>;
			resets = <&scmi_reset X5H_RESET_DOMAIN_ID_VIN061>;
			linux,uio-name = "vin_61";
		};

		vin_62: video@c4932000 {
			compatible = "generic-uio";
			reg = <0 0xc4932000 0 0x1000>;
			interrupts = <GIC_SPI 560 IRQ_TYPE_LEVEL_HIGH>;
			power-domains = <&scmi_devpd X5H_POWER_DOMAIN_ID_VIO2>;
			clocks = <&scmi_clk X5H_CLOCK_ID_VIN062>;
			resets = <&scmi_reset X5H_RESET_DOMAIN_ID_VIN062>;
			linux,uio-name = "vin_62";
		};

		vin_63: video@c4933000 {
			compatible = "generic-uio";
			reg = <0 0xc4933000 0 0x1000>;
			interrupts = <GIC_SPI 561 IRQ_TYPE_LEVEL_HIGH>;
			power-domains = <&scmi_devpd X5H_POWER_DOMAIN_ID_VIO2>;
			clocks = <&scmi_clk X5H_CLOCK_ID_VIN063>;
			resets = <&scmi_reset X5H_RESET_DOMAIN_ID_VIN063>;
			linux,uio-name = "vin_63";
		};

		vin_64: video@c4934000 {
			compatible = "generic-uio";
			reg = <0 0xc4934000 0 0x1000>;
			interrupts = <GIC_SPI 562 IRQ_TYPE_LEVEL_HIGH>;
			power-domains = <&scmi_devpd X5H_POWER_DOMAIN_ID_VIO2>;
			clocks = <&scmi_clk X5H_CLOCK_ID_VIN064>;
			resets = <&scmi_reset X5H_RESET_DOMAIN_ID_VIN064>;
			linux,uio-name = "vin_64";
		};

		vin_65: video@c4935000 {
			compatible = "generic-uio";
			reg = <0 0xc4935000 0 0x1000>;
			interrupts = <GIC_SPI 563 IRQ_TYPE_LEVEL_HIGH>;
			power-domains = <&scmi_devpd X5H_POWER_DOMAIN_ID_VIO2>;
			clocks = <&scmi_clk X5H_CLOCK_ID_VIN065>;
			resets = <&scmi_reset X5H_RESET_DOMAIN_ID_VIN065>;
			linux,uio-name = "vin_65";
		};

		vin_66: video@c4936000 {
			compatible = "generic-uio";
			reg = <0 0xc4936000 0 0x1000>;
			interrupts = <GIC_SPI 564 IRQ_TYPE_LEVEL_HIGH>;
			power-domains = <&scmi_devpd X5H_POWER_DOMAIN_ID_VIO2>;
			clocks = <&scmi_clk X5H_CLOCK_ID_VIN066>;
			resets = <&scmi_reset X5H_RESET_DOMAIN_ID_VIN066>;
			linux,uio-name = "vin_66";
		};

		vin_67: video@c4937000 {
			compatible = "generic-uio";
			reg = <0 0xc4937000 0 0x1000>;
			interrupts = <GIC_SPI 565 IRQ_TYPE_LEVEL_HIGH>;
			power-domains = <&scmi_devpd X5H_POWER_DOMAIN_ID_VIO2>;
			clocks = <&scmi_clk X5H_CLOCK_ID_VIN067>;
			resets = <&scmi_reset X5H_RESET_DOMAIN_ID_VIN067>;
			linux,uio-name = "vin_67";
		};

		vin_70: video@c4938000 {
			compatible = "generic-uio";
			reg = <0 0xc4938000 0 0x1000>;
			interrupts = <GIC_SPI 566 IRQ_TYPE_LEVEL_HIGH>;
			power-domains = <&scmi_devpd X5H_POWER_DOMAIN_ID_VIO2>;
			clocks = <&scmi_clk X5H_CLOCK_ID_VIN070>;
			resets = <&scmi_reset X5H_RESET_DOMAIN_ID_VIN070>;
			linux,uio-name = "vin_70";
		};

		vin_71: video@c4939000 {
			compatible = "generic-uio";
			reg = <0 0xc4939000 0 0x1000>;
			interrupts = <GIC_SPI 567 IRQ_TYPE_LEVEL_HIGH>;
			power-domains = <&scmi_devpd X5H_POWER_DOMAIN_ID_VIO2>;
			clocks = <&scmi_clk X5H_CLOCK_ID_VIN071>;
			resets = <&scmi_reset X5H_RESET_DOMAIN_ID_VIN071>;
			linux,uio-name = "vin_71";
		};

		vin_72: video@c493a000 {
			compatible = "generic-uio";
			reg = <0 0xc493a000 0 0x1000>;
			interrupts = <GIC_SPI 568 IRQ_TYPE_LEVEL_HIGH>;
			power-domains = <&scmi_devpd X5H_POWER_DOMAIN_ID_VIO2>;
			clocks = <&scmi_clk X5H_CLOCK_ID_VIN072>;
			resets = <&scmi_reset X5H_RESET_DOMAIN_ID_VIN072>;
			linux,uio-name = "vin_72";
		};

		vin_73: video@c493b000 {
			compatible = "generic-uio";
			reg = <0 0xc493b000 0 0x1000>;
			interrupts = <GIC_SPI 569 IRQ_TYPE_LEVEL_HIGH>;
			power-domains = <&scmi_devpd X5H_POWER_DOMAIN_ID_VIO2>;
			clocks = <&scmi_clk X5H_CLOCK_ID_VIN073>;
			resets = <&scmi_reset X5H_RESET_DOMAIN_ID_VIN073>;
			linux,uio-name = "vin_73";
		};

		vin_74: video@c493c000 {
			compatible = "generic-uio";
			reg = <0 0xc493c000 0 0x1000>;
			interrupts = <GIC_SPI 570 IRQ_TYPE_LEVEL_HIGH>;
			power-domains = <&scmi_devpd X5H_POWER_DOMAIN_ID_VIO2>;
			clocks = <&scmi_clk X5H_CLOCK_ID_VIN074>;
			resets = <&scmi_reset X5H_RESET_DOMAIN_ID_VIN074>;
			linux,uio-name = "vin_74";
		};

		vin_75: video@c493d000 {
			compatible = "generic-uio";
			reg = <0 0xc493d000 0 0x1000>;
			interrupts = <GIC_SPI 571 IRQ_TYPE_LEVEL_HIGH>;
			power-domains = <&scmi_devpd X5H_POWER_DOMAIN_ID_VIO2>;
			clocks = <&scmi_clk X5H_CLOCK_ID_VIN075>;
			resets = <&scmi_reset X5H_RESET_DOMAIN_ID_VIN075>;
			linux,uio-name = "vin_75";
		};

		vin_76: video@c493e000 {
			compatible = "generic-uio";
			reg = <0 0xc493e000 0 0x1000>;
			interrupts = <GIC_SPI 572 IRQ_TYPE_LEVEL_HIGH>;
			power-domains = <&scmi_devpd X5H_POWER_DOMAIN_ID_VIO2>;
			clocks = <&scmi_clk X5H_CLOCK_ID_VIN076>;
			resets = <&scmi_reset X5H_RESET_DOMAIN_ID_VIN076>;
			linux,uio-name = "vin_76";
		};

		vin_77: video@c493f000 {
			compatible = "generic-uio";
			reg = <0 0xc493f000 0 0x1000>;
			interrupts = <GIC_SPI 573 IRQ_TYPE_LEVEL_HIGH>;
			power-domains = <&scmi_devpd X5H_POWER_DOMAIN_ID_VIO2>;
			clocks = <&scmi_clk X5H_CLOCK_ID_VIN077>;
			resets = <&scmi_reset X5H_RESET_DOMAIN_ID_VIN077>;
			linux,uio-name = "vin_77";
		};

		vin_80: video@c4940000 {
			compatible = "generic-uio";
			reg = <0 0xc4940000 0 0x1000>;
			interrupts = <GIC_SPI 574 IRQ_TYPE_LEVEL_HIGH>;
			power-domains = <&scmi_devpd X5H_POWER_DOMAIN_ID_VIO2>;
			clocks = <&scmi_clk X5H_CLOCK_ID_VIN080>;
			resets = <&scmi_reset X5H_RESET_DOMAIN_ID_VIN080>;
			linux,uio-name = "vin_80";
		};

		vin_81: video@c4941000 {
			compatible = "generic-uio";
			reg = <0 0xc4941000 0 0x1000>;
			interrupts = <GIC_SPI 575 IRQ_TYPE_LEVEL_HIGH>;
			power-domains = <&scmi_devpd X5H_POWER_DOMAIN_ID_VIO2>;
			clocks = <&scmi_clk X5H_CLOCK_ID_VIN081>;
			resets = <&scmi_reset X5H_RESET_DOMAIN_ID_VIN081>;
			linux,uio-name = "vin_81";
		};

		vin_82: video@c4942000 {
			compatible = "generic-uio";
			reg = <0 0xc4942000 0 0x1000>;
			interrupts = <GIC_SPI 576 IRQ_TYPE_LEVEL_HIGH>;
			power-domains = <&scmi_devpd X5H_POWER_DOMAIN_ID_VIO2>;
			clocks = <&scmi_clk X5H_CLOCK_ID_VIN082>;
			resets = <&scmi_reset X5H_RESET_DOMAIN_ID_VIN082>;
			linux,uio-name = "vin_82";
		};

		vin_83: video@c4943000 {
			compatible = "generic-uio";
			reg = <0 0xc4943000 0 0x1000>;
			interrupts = <GIC_SPI 577 IRQ_TYPE_LEVEL_HIGH>;
			power-domains = <&scmi_devpd X5H_POWER_DOMAIN_ID_VIO2>;
			clocks = <&scmi_clk X5H_CLOCK_ID_VIN083>;
			resets = <&scmi_reset X5H_RESET_DOMAIN_ID_VIN083>;
			linux,uio-name = "vin_83";
		};

		vin_84: video@c4944000 {
			compatible = "generic-uio";
			reg = <0 0xc4944000 0 0x1000>;
			interrupts = <GIC_SPI 578 IRQ_TYPE_LEVEL_HIGH>;
			power-domains = <&scmi_devpd X5H_POWER_DOMAIN_ID_VIO2>;
			clocks = <&scmi_clk X5H_CLOCK_ID_VIN084>;
			resets = <&scmi_reset X5H_RESET_DOMAIN_ID_VIN084>;
			linux,uio-name = "vin_84";
		};

		vin_85: video@c4945000 {
			compatible = "generic-uio";
			reg = <0 0xc4945000 0 0x1000>;
			interrupts = <GIC_SPI 579 IRQ_TYPE_LEVEL_HIGH>;
			power-domains = <&scmi_devpd X5H_POWER_DOMAIN_ID_VIO2>;
			clocks = <&scmi_clk X5H_CLOCK_ID_VIN085>;
			resets = <&scmi_reset X5H_RESET_DOMAIN_ID_VIN085>;
			linux,uio-name = "vin_85";
		};

		vin_86: video@c4946000 {
			compatible = "generic-uio";
			reg = <0 0xc4946000 0 0x1000>;
			interrupts = <GIC_SPI 580 IRQ_TYPE_LEVEL_HIGH>;
			power-domains = <&scmi_devpd X5H_POWER_DOMAIN_ID_VIO2>;
			clocks = <&scmi_clk X5H_CLOCK_ID_VIN086>;
			resets = <&scmi_reset X5H_RESET_DOMAIN_ID_VIN086>;
			linux,uio-name = "vin_86";
		};

		vin_87: video@c4947000 {
			compatible = "generic-uio";
			reg = <0 0xc4947000 0 0x1000>;
			interrupts = <GIC_SPI 581 IRQ_TYPE_LEVEL_HIGH>;
			power-domains = <&scmi_devpd X5H_POWER_DOMAIN_ID_VIO2>;
			clocks = <&scmi_clk X5H_CLOCK_ID_VIN087>;
			resets = <&scmi_reset X5H_RESET_DOMAIN_ID_VIN087>;
			linux,uio-name = "vin_87";
		};

		vin_90: video@c4948000 {
			compatible = "generic-uio";
			reg = <0 0xc4948000 0 0x1000>;
			interrupts = <GIC_SPI 582 IRQ_TYPE_LEVEL_HIGH>;
			power-domains = <&scmi_devpd X5H_POWER_DOMAIN_ID_VIO3>;
			clocks = <&scmi_clk X5H_CLOCK_ID_VIN090>;
			resets = <&scmi_reset X5H_RESET_DOMAIN_ID_VIN090>;
			linux,uio-name = "vin_90";
		};

		vin_91: video@c4949000 {
			compatible = "generic-uio";
			reg = <0 0xc4949000 0 0x1000>;
			interrupts = <GIC_SPI 583 IRQ_TYPE_LEVEL_HIGH>;
			power-domains = <&scmi_devpd X5H_POWER_DOMAIN_ID_VIO3>;
			clocks = <&scmi_clk X5H_CLOCK_ID_VIN091>;
			resets = <&scmi_reset X5H_RESET_DOMAIN_ID_VIN091>;
			linux,uio-name = "vin_91";
		};

		vin_92: video@c494a000 {
			compatible = "generic-uio";
			reg = <0 0xc494a000 0 0x1000>;
			interrupts = <GIC_SPI 584 IRQ_TYPE_LEVEL_HIGH>;
			power-domains = <&scmi_devpd X5H_POWER_DOMAIN_ID_VIO3>;
			clocks = <&scmi_clk X5H_CLOCK_ID_VIN092>;
			resets = <&scmi_reset X5H_RESET_DOMAIN_ID_VIN092>;
			linux,uio-name = "vin_92";
		};

		vin_93: video@c494b000 {
			compatible = "generic-uio";
			reg = <0 0xc494b000 0 0x1000>;
			interrupts = <GIC_SPI 585 IRQ_TYPE_LEVEL_HIGH>;
			power-domains = <&scmi_devpd X5H_POWER_DOMAIN_ID_VIO3>;
			clocks = <&scmi_clk X5H_CLOCK_ID_VIN093>;
			resets = <&scmi_reset X5H_RESET_DOMAIN_ID_VIN093>;
			linux,uio-name = "vin_93";
		};

		vin_94: video@c494c000 {
			compatible = "generic-uio";
			reg = <0 0xc494c000 0 0x1000>;
			interrupts = <GIC_SPI 586 IRQ_TYPE_LEVEL_HIGH>;
			power-domains = <&scmi_devpd X5H_POWER_DOMAIN_ID_VIO3>;
			clocks = <&scmi_clk X5H_CLOCK_ID_VIN094>;
			resets = <&scmi_reset X5H_RESET_DOMAIN_ID_VIN094>;
			linux,uio-name = "vin_94";
		};

		vin_95: video@c494d000 {
			compatible = "generic-uio";
			reg = <0 0xc494d000 0 0x1000>;
			interrupts = <GIC_SPI 587 IRQ_TYPE_LEVEL_HIGH>;
			power-domains = <&scmi_devpd X5H_POWER_DOMAIN_ID_VIO3>;
			clocks = <&scmi_clk X5H_CLOCK_ID_VIN095>;
			resets = <&scmi_reset X5H_RESET_DOMAIN_ID_VIN095>;
			linux,uio-name = "vin_95";
		};

		vin_96: video@c494e000 {
			compatible = "generic-uio";
			reg = <0 0xc494e000 0 0x1000>;
			interrupts = <GIC_SPI 588 IRQ_TYPE_LEVEL_HIGH>;
			power-domains = <&scmi_devpd X5H_POWER_DOMAIN_ID_VIO3>;
			clocks = <&scmi_clk X5H_CLOCK_ID_VIN096>;
			resets = <&scmi_reset X5H_RESET_DOMAIN_ID_VIN096>;
			linux,uio-name = "vin_96";
		};

		vin_97: video@c494f000 {
			compatible = "generic-uio";
			reg = <0 0xc494f000 0 0x1000>;
			interrupts = <GIC_SPI 589 IRQ_TYPE_LEVEL_HIGH>;
			power-domains = <&scmi_devpd X5H_POWER_DOMAIN_ID_VIO3>;
			clocks = <&scmi_clk X5H_CLOCK_ID_VIN097>;
			resets = <&scmi_reset X5H_RESET_DOMAIN_ID_VIN097>;
			linux,uio-name = "vin_97";
		};

		vin_100: video@c4950000 {
			compatible = "generic-uio";
			reg = <0 0xc4950000 0 0x1000>;
			interrupts = <GIC_SPI 590 IRQ_TYPE_LEVEL_HIGH>;
			power-domains = <&scmi_devpd X5H_POWER_DOMAIN_ID_VIO3>;
			clocks = <&scmi_clk X5H_CLOCK_ID_VIN100>;
			resets = <&scmi_reset X5H_RESET_DOMAIN_ID_VIN100>;
			linux,uio-name = "vin_100";
		};

		vin_101: video@c4951000 {
			compatible = "generic-uio";
			reg = <0 0xc4951000 0 0x1000>;
			interrupts = <GIC_SPI 591 IRQ_TYPE_LEVEL_HIGH>;
			power-domains = <&scmi_devpd X5H_POWER_DOMAIN_ID_VIO3>;
			clocks = <&scmi_clk X5H_CLOCK_ID_VIN101>;
			resets = <&scmi_reset X5H_RESET_DOMAIN_ID_VIN101>;
			linux,uio-name = "vin_101";
		};

		vin_102: video@c4952000 {
			compatible = "generic-uio";
			reg = <0 0xc4952000 0 0x1000>;
			interrupts = <GIC_SPI 592 IRQ_TYPE_LEVEL_HIGH>;
			power-domains = <&scmi_devpd X5H_POWER_DOMAIN_ID_VIO3>;
			clocks = <&scmi_clk X5H_CLOCK_ID_VIN102>;
			resets = <&scmi_reset X5H_RESET_DOMAIN_ID_VIN102>;
			linux,uio-name = "vin_102";
		};

		vin_103: video@c4953000 {
			compatible = "generic-uio";
			reg = <0 0xc4953000 0 0x1000>;
			interrupts = <GIC_SPI 593 IRQ_TYPE_LEVEL_HIGH>;
			power-domains = <&scmi_devpd X5H_POWER_DOMAIN_ID_VIO3>;
			clocks = <&scmi_clk X5H_CLOCK_ID_VIN103>;
			resets = <&scmi_reset X5H_RESET_DOMAIN_ID_VIN103>;
			linux,uio-name = "vin_103";
		};

		vin_104: video@c4954000 {
			compatible = "generic-uio";
			reg = <0 0xc4954000 0 0x1000>;
			interrupts = <GIC_SPI 594 IRQ_TYPE_LEVEL_HIGH>;
			power-domains = <&scmi_devpd X5H_POWER_DOMAIN_ID_VIO3>;
			clocks = <&scmi_clk X5H_CLOCK_ID_VIN104>;
			resets = <&scmi_reset X5H_RESET_DOMAIN_ID_VIN104>;
			linux,uio-name = "vin_104";
		};

		vin_105: video@c4955000 {
			compatible = "generic-uio";
			reg = <0 0xc4955000 0 0x1000>;
			interrupts = <GIC_SPI 595 IRQ_TYPE_LEVEL_HIGH>;
			power-domains = <&scmi_devpd X5H_POWER_DOMAIN_ID_VIO3>;
			clocks = <&scmi_clk X5H_CLOCK_ID_VIN105>;
			resets = <&scmi_reset X5H_RESET_DOMAIN_ID_VIN105>;
			linux,uio-name = "vin_105";
		};

		vin_106: video@c4956000 {
			compatible = "generic-uio";
			reg = <0 0xc4956000 0 0x1000>;
			interrupts = <GIC_SPI 596 IRQ_TYPE_LEVEL_HIGH>;
			power-domains = <&scmi_devpd X5H_POWER_DOMAIN_ID_VIO3>;
			clocks = <&scmi_clk X5H_CLOCK_ID_VIN106>;
			resets = <&scmi_reset X5H_RESET_DOMAIN_ID_VIN106>;
			linux,uio-name = "vin_106";
		};

		vin_107: video@c4957000 {
			compatible = "generic-uio";
			reg = <0 0xc4957000 0 0x1000>;
			interrupts = <GIC_SPI 597 IRQ_TYPE_LEVEL_HIGH>;
			power-domains = <&scmi_devpd X5H_POWER_DOMAIN_ID_VIO3>;
			clocks = <&scmi_clk X5H_CLOCK_ID_VIN107>;
			resets = <&scmi_reset X5H_RESET_DOMAIN_ID_VIN107>;
			linux,uio-name = "vin_107";
		};

		vin_110: video@c4958000 {
			compatible = "generic-uio";
			reg = <0 0xc4958000 0 0x1000>;
			interrupts = <GIC_SPI 598 IRQ_TYPE_LEVEL_HIGH>;
			power-domains = <&scmi_devpd X5H_POWER_DOMAIN_ID_VIO3>;
			clocks = <&scmi_clk X5H_CLOCK_ID_VIN110>;
			resets = <&scmi_reset X5H_RESET_DOMAIN_ID_VIN110>;
			linux,uio-name = "vin_110";
		};

		vin_111: video@c4959000 {
			compatible = "generic-uio";
			reg = <0 0xc4959000 0 0x1000>;
			interrupts = <GIC_SPI 599 IRQ_TYPE_LEVEL_HIGH>;
			power-domains = <&scmi_devpd X5H_POWER_DOMAIN_ID_VIO3>;
			clocks = <&scmi_clk X5H_CLOCK_ID_VIN111>;
			resets = <&scmi_reset X5H_RESET_DOMAIN_ID_VIN111>;
			linux,uio-name = "vin_111";
		};

		vin_112: video@c495a000 {
			compatible = "generic-uio";
			reg = <0 0xc495a000 0 0x1000>;
			interrupts = <GIC_SPI 600 IRQ_TYPE_LEVEL_HIGH>;
			power-domains = <&scmi_devpd X5H_POWER_DOMAIN_ID_VIO3>;
			clocks = <&scmi_clk X5H_CLOCK_ID_VIN112>;
			resets = <&scmi_reset X5H_RESET_DOMAIN_ID_VIN112>;
			linux,uio-name = "vin_112";
		};

		vin_113: video@c495b000 {
			compatible = "generic-uio";
			reg = <0 0xc495b000 0 0x1000>;
			interrupts = <GIC_SPI 601 IRQ_TYPE_LEVEL_HIGH>;
			power-domains = <&scmi_devpd X5H_POWER_DOMAIN_ID_VIO3>;
			clocks = <&scmi_clk X5H_CLOCK_ID_VIN113>;
			resets = <&scmi_reset X5H_RESET_DOMAIN_ID_VIN113>;
			linux,uio-name = "vin_113";
		};

		vin_114: video@c495c000 {
			compatible = "generic-uio";
			reg = <0 0xc495c000 0 0x1000>;
			interrupts = <GIC_SPI 602 IRQ_TYPE_LEVEL_HIGH>;
			power-domains = <&scmi_devpd X5H_POWER_DOMAIN_ID_VIO3>;
			clocks = <&scmi_clk X5H_CLOCK_ID_VIN114>;
			resets = <&scmi_reset X5H_RESET_DOMAIN_ID_VIN114>;
			linux,uio-name = "vin_114";
		};

		vin_115: video@c495d000 {
			compatible = "generic-uio";
			reg = <0 0xc495d000 0 0x1000>;
			interrupts = <GIC_SPI 603 IRQ_TYPE_LEVEL_HIGH>;
			power-domains = <&scmi_devpd X5H_POWER_DOMAIN_ID_VIO3>;
			clocks = <&scmi_clk X5H_CLOCK_ID_VIN115>;
			resets = <&scmi_reset X5H_RESET_DOMAIN_ID_VIN115>;
			linux,uio-name = "vin_115";
		};

		vin_116: video@c495e000 {
			compatible = "generic-uio";
			reg = <0 0xc495e000 0 0x1000>;
			interrupts = <GIC_SPI 604 IRQ_TYPE_LEVEL_HIGH>;
			power-domains = <&scmi_devpd X5H_POWER_DOMAIN_ID_VIO3>;
			clocks = <&scmi_clk X5H_CLOCK_ID_VIN116>;
			resets = <&scmi_reset X5H_RESET_DOMAIN_ID_VIN116>;
			linux,uio-name = "vin_116";
		};

		vin_117: video@c495f000 {
			compatible = "generic-uio";
			reg = <0 0xc495f000 0 0x1000>;
			interrupts = <GIC_SPI 605 IRQ_TYPE_LEVEL_HIGH>;
			power-domains = <&scmi_devpd X5H_POWER_DOMAIN_ID_VIO3>;
			clocks = <&scmi_clk X5H_CLOCK_ID_VIN117>;
			resets = <&scmi_reset X5H_RESET_DOMAIN_ID_VIN117>;
			linux,uio-name = "vin_117";
		};

		csi0: video@c4400000 {
			compatible = "generic-uio";
			reg = <0 0xc4400000 0 0x80000>;
			interrupts = <GIC_SPI 498 IRQ_TYPE_LEVEL_HIGH>;
			power-domains = <&scmi_devpd X5H_POWER_DOMAIN_ID_VIO0>;
			clocks = <&scmi_clk X5H_CLOCK_ID_CSITOP0>;
			resets = <&scmi_reset X5H_RESET_DOMAIN_ID_CSITOP0>;
			linux,uio-name = "csi_00";
		};

		csi1: video@c4480000 {
			compatible = "generic-uio";
			reg = <0 0xc4480000 0 0x80000>;
			interrupts = <GIC_SPI 499 IRQ_TYPE_LEVEL_HIGH>;
			power-domains = <&scmi_devpd X5H_POWER_DOMAIN_ID_VIO1>;
			clocks = <&scmi_clk X5H_CLOCK_ID_CSITOP1>;
			resets = <&scmi_reset X5H_RESET_DOMAIN_ID_CSITOP1>;
			linux,uio-name = "csi_01";
		};

		csi2: video@c4500000 {
			compatible = "generic-uio";
			reg = <0 0xc4500000 0 0x80000>;
			interrupts = <GIC_SPI 500 IRQ_TYPE_LEVEL_HIGH>;
			power-domains = <&scmi_devpd X5H_POWER_DOMAIN_ID_VIO2>;
			clocks = <&scmi_clk X5H_CLOCK_ID_CSITOP2>;
			resets = <&scmi_reset X5H_RESET_DOMAIN_ID_CSITOP2>;
			linux,uio-name = "csi_02";
		};

		csi3: video@c4580000 {
			compatible = "generic-uio";
			reg = <0 0xc4580000 0 0x80000>;
			interrupts = <GIC_SPI 501 IRQ_TYPE_LEVEL_HIGH>;
			power-domains = <&scmi_devpd X5H_POWER_DOMAIN_ID_VIO3>;
			clocks = <&scmi_clk X5H_CLOCK_ID_CSITOP3>;
			resets = <&scmi_reset X5H_RESET_DOMAIN_ID_CSITOP3>;
			linux,uio-name = "csi_03";
		};

		rfso0: rfso@c05e0000 {
			compatible="generic-uio";
			reg=<0 0xc05e0000 0 0x1000>;
			linux,uio-name="rfso_00";
		};

		rfso1: rfso@c05e1000 {
			compatible="generic-uio";
			reg=<0 0xc05e1000 0 0x1000>;
			linux,uio-name="rfso_01";
		};

		rfso2: rfso@c05e2000 {
			compatible="generic-uio";
			reg=<0 0xc05e2000 0 0x1000>;
			linux,uio-name="rfso_02";
		};

		rfso3: rfso@c05e3000 {
			compatible="generic-uio";
			reg=<0 0xc05e3000 0 0x1000>;
			linux,uio-name="rfso_03";
		};

		rfso4: rfso@c05e4000 {
			compatible="generic-uio";
			reg=<0 0xc05e4000 0 0x1000>;
			linux,uio-name="rfso_04";
		};

		rfso5: rfso@c05e5000 {
			compatible="generic-uio";
			reg=<0 0xc05e5000 0 0x1000>;
			linux,uio-name="rfso_05";
		};

		rfso6: rfso@c05e6000 {
			compatible="generic-uio";
			reg=<0 0xc05e6000 0 0x1000>;
			linux,uio-name="rfso_06";
		};

		rfso7: rfso@c05e7000 {
			compatible="generic-uio";
			reg=<0 0xc05e7000 0 0x1000>;
			linux,uio-name="rfso_07";
		};

		rfso8: rfso@c05e8000 {
			compatible="generic-uio";
			reg=<0 0xc05e8000 0 0x1000>;
			linux,uio-name="rfso_08";
		};

		rfso9: rfso@c05e9000 {
			compatible="generic-uio";
			reg=<0 0xc05e9000 0 0x1000>;
			linux,uio-name="rfso_09";
		};

		rfso10: rfso@c05ea000 {
			compatible="generic-uio";
			reg=<0 0xc05ea000 0 0x1000>;
			linux,uio-name="rfso_10";
		};

		rfso11: rfso@c05eb000 {
			compatible="generic-uio";
			reg=<0 0xc05eb000 0 0x1000>;
			linux,uio-name="rfso_11";
		};

		rfso12: rfso@c05ec000 {
			compatible="generic-uio";
			reg=<0 0xc05ec000 0 0x1000>;
			linux,uio-name="rfso_12";
		};

		rfso13: rfso@c05ed000 {
			compatible="generic-uio";
			reg=<0 0xc05ed000 0 0x1000>;
			linux,uio-name="rfso_13";
		};

		rfso14: rfso@c05ee000 {
			compatible="generic-uio";
			reg=<0 0xc05ee000 0 0x1000>;
			linux,uio-name="rfso_14";
		};

		rfso15: rfso@c05ef000 {
			compatible="generic-uio";
			reg=<0 0xc05ef000 0 0x1000>;
			linux,uio-name="rfso_15";
		};

		rfso16: rfso@c05f0000 {
			compatible="generic-uio";
			reg=<0 0xc05f0000 0 0x1000>;
			linux,uio-name="rfso_16";
		};

		rfso17: rfso@c05f1000 {
			compatible="generic-uio";
			reg=<0 0xc05f1000 0 0x1000>;
			linux,uio-name="rfso_17";
		};

		rfso18: rfso@c05f2000 {
			compatible="generic-uio";
			reg=<0 0xc05f2000 0 0x1000>;
			linux,uio-name="rfso_18";
		};

		rfso19: rfso@c05f3000 {
			compatible="generic-uio";
			reg=<0 0xc05f3000 0 0x1000>;
			linux,uio-name="rfso_19";
		};

		rfso_common {
			compatible="generic-uio";
			reg=<0 0x0 0 0x0>;
			interrupts=<GIC_SPI 4086 IRQ_TYPE_LEVEL_HIGH>;
			linux,uio-name="rfso_common_00";
		};
	};
};
